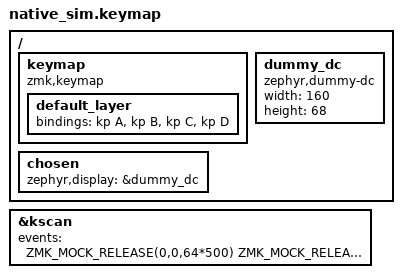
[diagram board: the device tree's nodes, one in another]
#include <behaviors.dtsi>
#include <dt-bindings/zmk/keys.h>
#include <dt-bindings/zmk/kscan_mock.h>

/ {
    keymap {
        compatible = "zmk,keymap";
        default_layer {
            bindings = <&kp A &kp B &kp C &kp D>;
        };
    };

    chosen {
        zephyr,display = &dummy_dc;
    };
    dummy_dc: dummy_dc {
        compatible = "zephyr,dummy-dc";
        width = <160>;
        height = <68>;
    };
};


&kscan {
    events = <
        ZMK_MOCK_RELEASE(0,0,64*500)
        ZMK_MOCK_RELEASE(0,0,64*500)
        ZMK_MOCK_RELEASE(0,0,64*500)
        ZMK_MOCK_RELEASE(0,0,64*500)
        // no meaningful events, we'll have a demo mode cycling through synthetic states
    >;
};
